# CY8C5888LTI_LP097 register map
File version: 0.1
CY8C58LP
Registers are 8-bit, read-write, no defined reset value unless marked. A register's access mark holds for its fields unless they carry their own. Offsets are from the block's base; lines under a group give offsets from that group; [hi:lo] are bit positions; {n}, {i} and the like mark numbered series; 'fields as' and 'values as' point back to an identical list; <NAME> marks a mode.

## Memory map
0x00000000 Downstream_Level_Sensor_UART — UART
0x00000000 UART_Telit — UART
0x00000000 Telit_ControlReg
0x00000000 BottleCounter
0x00000000 Level_Sensor_UART — UART
0x00000000 SleepTimer
0x00000000 RTC
0x00000000 Debug_UART — UART
0x00000000 ADC

## Downstream_Level_Sensor_UART — UART
Base 0x00000000
0x40006428 RX_Downstream_Level_Sensor_UART_RX_ADDRESS1 — RX Address1 Register
0x40006438 RX_Downstream_Level_Sensor_UART_RX_ADDRESS2 — RX Address2 Register
0x40006448 RX_Downstream_Level_Sensor_UART_RX_DATA — RX Data Register
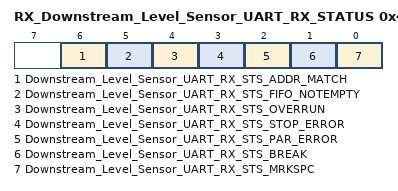
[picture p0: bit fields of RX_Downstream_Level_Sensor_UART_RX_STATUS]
0x40006468 RX_Downstream_Level_Sensor_UART_RX_STATUS — RX status register
  [6] Downstream_Level_Sensor_UART_RX_STS_ADDR_MATCH ro, [5] Downstream_Level_Sensor_UART_RX_STS_FIFO_NOTEMPTY ro, [4] Downstream_Level_Sensor_UART_RX_STS_OVERRUN ro, [3] Downstream_Level_Sensor_UART_RX_STS_STOP_ERROR ro, [2] Downstream_Level_Sensor_UART_RX_STS_PAR_ERROR ro, [1] Downstream_Level_Sensor_UART_RX_STS_BREAK ro, [0] Downstream_Level_Sensor_UART_RX_STS_MRKSPC ro

## UART_Telit — UART
Base 0x00000000
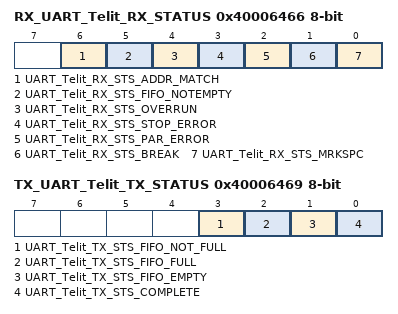
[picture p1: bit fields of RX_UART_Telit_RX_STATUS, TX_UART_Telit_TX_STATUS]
0x40006466 RX_UART_Telit_RX_STATUS — RX status register
  [6] UART_Telit_RX_STS_ADDR_MATCH ro, [5] UART_Telit_RX_STS_FIFO_NOTEMPTY ro, [4] UART_Telit_RX_STS_OVERRUN ro, [3] UART_Telit_RX_STS_STOP_ERROR ro, [2] UART_Telit_RX_STS_PAR_ERROR ro, [1] UART_Telit_RX_STS_BREAK ro, [0] UART_Telit_RX_STS_MRKSPC ro
0x40006469 TX_UART_Telit_TX_STATUS — TX status register
  [3] UART_Telit_TX_STS_FIFO_NOT_FULL ro, [2] UART_Telit_TX_STS_FIFO_FULL ro, [1] UART_Telit_TX_STS_FIFO_EMPTY ro, [0] UART_Telit_TX_STS_COMPLETE ro
0x40006525 RX_UART_Telit_RX_ADDRESS1 — RX Address1 Register
0x40006535 RX_UART_Telit_RX_ADDRESS2 — RX Address2 Register
0x40006545 RX_UART_Telit_RX_DATA — RX Data Register
0x4000654A TX_UART_Telit_TX_DATA — TX Data Register

## Telit_ControlReg
Base 0x00000000
0x40006477 Telit_ControlReg_CONTROL_REG

## BottleCounter
Base 0x00000000
0x40006402 BottleCounter_COUNTER 16-bit — UDB.A0 - Current Counter Value
0x40006422 BottleCounter_PERIOD 16-bit — UDB.D0 - Assigned Period
0x40006432 BottleCounter_COMPARE 16-bit — UDB.D1 - Assigned Compare Value
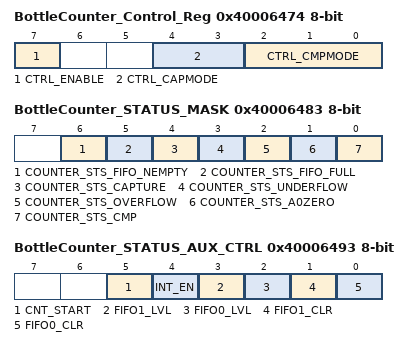
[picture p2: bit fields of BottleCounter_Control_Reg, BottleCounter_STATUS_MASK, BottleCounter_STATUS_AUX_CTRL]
0x40006474 BottleCounter_Control_Reg — UDB Control Register - Assigned Control Register Value
  [7] CTRL_ENABLE — Enable Counter
  [4:3] CTRL_CAPMODE — Capture mode
  [2:0] CTRL_CMPMODE — Compare mode
0x40006483 BottleCounter_STATUS_MASK — UDB Status bits Interrupt Mask Enable Register
  [6] COUNTER_STS_FIFO_NEMPTY — FIFO Not Empty Status
  [5] COUNTER_STS_FIFO_FULL — FIFO Full Status
  [4] COUNTER_STS_CAPTURE — Capture Status
  [3] COUNTER_STS_UNDERFLOW — Underflow status
  [2] COUNTER_STS_OVERFLOW — Overflow status
  [1] COUNTER_STS_A0ZERO — A0 Zero ouput status
  [0] COUNTER_STS_CMP — Compare output status
0x40006493 BottleCounter_STATUS_AUX_CTRL — UDB Auxilliary Control Register
  [5] CNT_START — FIFO0 clear
    0=E_CNT_START0 (Disable counter); 1=E_CNT_START1 (Enable counter)
  [4] INT_EN
    0=E_INT_EN0 (Interrupt disabled); 1=E_INT_EN1 (Interrupt enabled)
  [3] FIFO1_LVL — FIFO level
    0=E_FIFO_LVL_0 (FIFO LVL: input mode: FIFO not full; output mode: FIFO not empty); 1=E_FIFO_LVL_1 (FIFO LVL: input mode: FIFO at least 1/2 empty; output mode: FIFO at least 1/2 full)
  [2] FIFO0_LVL — FIFO level
    values as FIFO1_LVL
  [1] FIFO1_CLR — FIFO1 clear
    0=E_FIFO_CLR_0 (Normal FIFO operation); 1=E_FIFO_CLR_1 (Clear FIFO state)
  [0] FIFO0_CLR — FIFO0 clear
    values as FIFO1_CLR

## Level_Sensor_UART — UART
Base 0x00000000
0x40006425 RX_Level_Sensor_UART_RX_ADDRESS1 — RX Address1 Register
0x40006435 RX_Level_Sensor_UART_RX_ADDRESS2 — RX Address2 Register
0x40006445 RX_Level_Sensor_UART_RX_DATA — RX Data Register
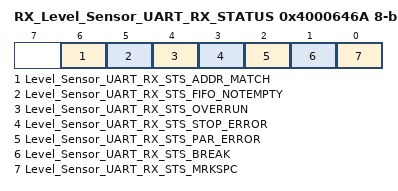
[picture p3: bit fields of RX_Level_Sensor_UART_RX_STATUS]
0x4000646A RX_Level_Sensor_UART_RX_STATUS — RX status register
  [6] Level_Sensor_UART_RX_STS_ADDR_MATCH ro, [5] Level_Sensor_UART_RX_STS_FIFO_NOTEMPTY ro, [4] Level_Sensor_UART_RX_STS_OVERRUN ro, [3] Level_Sensor_UART_RX_STS_STOP_ERROR ro, [2] Level_Sensor_UART_RX_STS_PAR_ERROR ro, [1] Level_Sensor_UART_RX_STS_BREAK ro, [0] Level_Sensor_UART_RX_STS_MRKSPC ro
